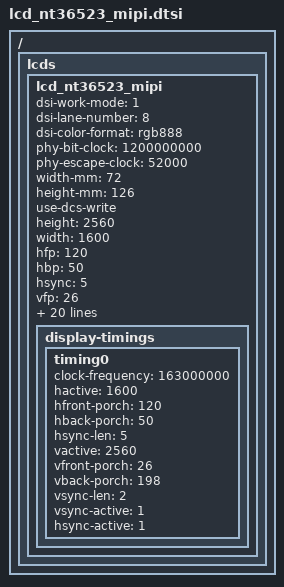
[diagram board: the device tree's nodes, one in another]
// SPDX-License-Identifier: GPL-2.0

/ { lcds: lcds {
	lcd_nt36523_mipi: lcd_nt36523_mipi {
		dsi-work-mode = <1>; /* video burst mode*/
		dsi-lane-number = <8>;
		dsi-color-format = "rgb888";

		phy-bit-clock = <1200000000>;	/* kbps */
		phy-escape-clock = <52000>;/* kHz */

		width-mm = <72>;
		height-mm = <126>;

		use-dcs-write;

		/*mipi info*/
		height = <2560>;
		width = <1600>;
		hfp = <120>;
		hbp = <50>;
		hsync = <5>;
		vfp = <26>;
		vbp = <198>;
		vsync = <2>;
		fps = <60>;
		work-mode = <0>;
		rgb-mode = <3>;
		lane-number = <8>;
		phy-freq = <1050000>;
		split-enable = <1>;
		eotp-enable = <0>;
		burst-mode = <2>;
		esd-check-enable = <0>;

		te-esd-en = <0>;

		/* DSI_CMD, DSI_MODE, timeout, len, cmd  */
		initial-command = [
			39 01 00 02 FF 20
			39 01 00 02 FB 01
			39 01 00 02 05 69
			39 01 00 02 07 32
			39 01 00 02 08 32
			39 01 00 02 0D 63
			39 01 00 02 0E 41
			39 01 00 02 0F 41
			39 01 00 02 94 00
			39 01 00 02 95 C3
			39 01 00 02 96 EB
			39 01 00 02 30 11
			39 01 00 02 58 40
			39 01 00 02 6D AA
			39 01 00 02 75 C4
			39 01 00 02 77 B3
			39 01 00 02 FF 22
			39 01 00 02 FB 01
			39 01 00 02 9F 5E
			39 01 00 02 6F 01
			39 01 00 02 70 11
			39 01 00 02 73 01
			39 01 00 02 74 87
			39 01 00 02 76 01
			39 01 00 02 77 87
			39 01 00 02 A0 3F
			39 01 00 02 A9 50
			39 01 00 02 AA 28
			39 01 00 02 AB 28
			39 01 00 02 AD 10
			39 01 00 02 B8 00
			39 01 00 02 B9 87
			39 01 00 02 BA 87
			39 01 00 02 BB 87
			39 01 00 02 BE 04
			39 01 00 02 BF 87
			39 01 00 02 C0 04
			39 01 00 02 C1 97
			39 01 00 02 C2 00
			39 01 00 02 C5 00
			39 01 00 02 C6 01
			39 01 00 02 C7 48
			39 01 00 02 CA 43
			39 01 00 02 CB 3C
			39 01 00 02 CE 00
			39 01 00 02 CF 43
			39 01 00 02 D0 3C
			39 01 00 02 D3 43
			39 01 00 02 D4 3C
			39 01 00 02 D7 00
			39 01 00 02 DC 43
			39 01 00 02 DD 3C
			39 01 00 02 E1 43
			39 01 00 02 E2 3C
			39 01 00 02 F2 00
			39 01 00 02 F3 01
			39 01 00 02 F4 48
			39 01 00 02 FF 24
			39 01 00 02 FB 01
			39 01 00 02 00 03
			39 01 00 02 01 27
			39 01 00 02 02 27
			39 01 00 02 03 27
			39 01 00 02 04 00
			39 01 00 02 05 00
			39 01 00 02 06 00
			39 01 00 02 07 04
			39 01 00 02 08 05
			39 01 00 02 09 23
			39 01 00 02 0A 22
			39 01 00 02 0B 28
			39 01 00 02 0C 28
			39 01 00 02 0D 21
			39 01 00 02 0E 29
			39 01 00 02 0F 29
			39 01 00 02 10 0C
			39 01 00 02 11 0D
			39 01 00 02 12 0E
			39 01 00 02 13 0F
			39 01 00 02 14 26
			39 01 00 02 15 26
			39 01 00 02 16 03
			39 01 00 02 17 27
			39 01 00 02 18 27
			39 01 00 02 19 27
			39 01 00 02 1A 00
			39 01 00 02 1B 00
			39 01 00 02 1C 00
			39 01 00 02 1D 04
			39 01 00 02 1E 05
			39 01 00 02 1F 23
			39 01 00 02 20 22
			39 01 00 02 21 28
			39 01 00 02 22 28
			39 01 00 02 23 21
			39 01 00 02 24 29
			39 01 00 02 25 29
			39 01 00 02 26 0C
			39 01 00 02 27 0D
			39 01 00 02 28 0E
			39 01 00 02 29 0F
			39 01 00 02 2A 26
			39 01 00 02 2B 26
			39 01 00 02 2F 02
			39 01 00 02 30 01
			39 01 00 02 33 01
			39 01 00 02 34 02
			39 01 00 02 37 22
			39 01 00 02 39 00
			39 01 00 02 3A 01
			39 01 00 02 3B 86
			39 01 00 02 3D 02
			39 01 00 02 4D 43
			39 01 00 02 4E 21
			39 01 00 02 51 12
			39 01 00 02 52 34
			39 01 00 03 55 0B 0B
			39 01 00 02 56 04
			39 01 00 02 58 10
			39 01 00 02 59 20
			39 01 00 02 5A 6A
			39 01 00 02 5B 63
			39 01 00 03 5E 00 0B
			39 01 00 02 5F 00
			39 01 00 02 65 82
			39 01 00 02 96 73
			39 01 00 02 B1 0E
			39 01 00 02 B2 0D
			39 01 00 02 C4 2F
			39 01 00 0D B6 05 00 05 00 00 00 00 00 05 05 00 00
			39 01 00 02 60 C8
			39 01 00 02 61 00
			39 01 00 02 63 A0
			39 01 00 02 91 40
			39 01 00 02 92 87
			39 01 00 02 93 1A
			39 01 00 02 94 C8
			39 01 00 02 95 80
			39 01 00 02 AB 22
			39 01 00 02 D7 55
			39 01 00 02 DA 0A
			39 01 00 02 DE 08
			39 01 00 02 DB 71
			39 01 00 02 DC 87
			39 01 00 02 DD 22
			39 01 00 02 DF 01
			39 01 00 02 E0 87
			39 01 00 02 E1 01
			39 01 00 02 E2 87
			39 01 00 02 E3 01
			39 01 00 02 E4 87
			39 01 00 02 E5 01
			39 01 00 02 E6 87
			39 01 00 02 5C 00
			39 01 00 02 5D 00
			39 01 00 02 8D 00
			39 01 00 02 8E 00
			39 01 00 02 B5 90
			39 01 00 02 C2 DF
			39 01 00 02 65 C2
			39 01 00 02 B1 0E
			39 01 00 02 B2 0D
			39 01 00 02 FF 25
			39 01 00 02 FB 01
			39 01 00 02 05 00
			39 01 00 02 19 07
			39 01 00 02 1F 6A
			39 01 00 02 20 63
			39 01 00 02 26 6A
			39 01 00 02 27 63
			39 01 00 02 33 6A
			39 01 00 02 34 63
			39 01 00 02 3F 00
			39 01 00 02 44 01
			39 01 00 02 45 48
			39 01 00 02 48 6A
			39 01 00 02 49 63
			39 01 00 02 5B 00
			39 01 00 02 5C 00
			39 01 00 02 5D 00
			39 01 00 02 5E D0
			39 01 00 02 61 6A
			39 01 00 02 62 63
			39 01 00 02 F1 10
			39 01 00 02 FF 2A
			39 01 00 02 FB 01
			39 01 00 02 64 96
			39 01 00 02 6A 9E
			39 01 00 02 76 9E
			39 01 00 02 79 96
			39 01 00 02 7C 96
			39 01 00 02 7F 96
			39 01 00 02 82 16
			39 01 00 02 85 9E
			39 01 00 02 88 96
			39 01 00 02 A2 FF
			39 01 00 02 A3 FF
			39 01 00 02 A4 F3
			39 01 00 02 A5 FF
			39 01 00 02 D6 08
			39 01 00 02 FF 26
			39 01 00 02 FB 01
			39 01 00 02 00 81
			39 01 00 02 01 30
			39 01 00 02 02 31
			39 01 00 02 0A F2
			39 01 00 02 04 5E
			39 01 00 02 06 32
			39 01 00 02 0A F5
			39 01 00 02 0C 16
			39 01 00 02 0D 0D
			39 01 00 02 0F 00
			39 01 00 02 11 00
			39 01 00 02 12 50
			39 01 00 02 13 60
			39 01 00 02 14 70
			39 01 00 02 15 00
			39 01 00 02 16 10
			39 01 00 02 17 A0
			39 01 00 02 18 86
			39 01 00 02 19 16
			39 01 00 02 1A 7F
			39 01 00 02 1B 15
			39 01 00 02 1C 90
			39 01 00 02 22 00
			39 01 00 02 23 00
			39 01 00 02 2A 16
			39 01 00 02 2B 7F
			39 01 00 02 1D 00
			39 01 00 02 1E 87
			39 01 00 02 1F 87
			39 01 00 02 24 00
			39 01 00 02 25 87
			39 01 00 02 2F 04
			39 01 00 02 30 87
			39 01 00 02 31 04
			39 01 00 02 32 9F
			39 01 00 02 39 00
			39 01 00 02 3A 87
			39 01 00 02 20 01
			39 01 00 02 33 66
			39 01 00 02 34 66
			39 01 00 02 35 66
			39 01 00 02 8B 50
			39 01 00 02 FF 25
			39 01 00 02 FB 01
			39 01 00 02 13 02
			39 01 00 02 14 41
			39 01 00 02 BC 02
			39 01 00 02 BD 41
			39 01 00 02 FF 2A
			39 01 00 02 FB 01
			39 01 00 02 99 95
			39 01 00 02 9A 03
			39 01 00 02 FF 27
			39 01 00 02 FB 01
			39 01 00 02 56 06
			39 01 00 02 58 80
			39 01 00 02 59 93
			39 01 00 02 5A 00
			39 01 00 02 5B 02
			39 01 00 02 5C 00
			39 01 00 02 5D 00
			39 01 00 02 5E 20
			39 01 00 02 5F 10
			39 01 00 02 60 00
			39 01 00 02 61 2A
			39 01 00 02 62 00
			39 01 00 02 63 01
			39 01 00 02 64 56
			39 01 00 02 65 29
			39 01 00 02 66 00
			39 01 00 02 67 01
			39 01 00 02 68 57
			39 01 00 02 3F 40
			39 01 00 02 76 02
			39 01 00 02 FF 2A
			39 01 00 02 FB 01
			39 01 00 02 22 2F
			39 01 00 02 23 08
			39 01 00 02 24 00
			39 01 00 02 25 87
			39 01 00 02 27 00
			39 01 00 02 28 1A
			39 01 00 02 29 00
			39 01 00 02 2A 1A
			39 01 00 02 2B 00
			39 01 00 02 2D 1A
			39 01 00 02 2F 00
			39 01 00 02 30 87
			39 01 00 02 32 00
			39 01 00 02 33 1A
			39 01 00 02 34 00
			39 01 00 02 35 1A
			39 01 00 02 36 00
			39 01 00 02 37 1A
			39 01 00 02 38 03
			39 01 00 02 39 87
			39 01 00 02 3B 00
			39 01 00 02 3D 1A
			39 01 00 02 3F 00
			39 01 00 02 40 1A
			39 01 00 02 41 00
			39 01 00 02 42 1A
			39 01 00 02 FF 27
			39 01 00 02 FB 01
			39 01 00 02 30 02
			39 01 00 02 76 02
			39 01 00 02 96 02
			39 01 00 02 F8 02
			39 01 00 02 FF E0
			39 01 00 02 FB 01
			39 01 00 02 14 60
			39 01 00 02 16 C0
			39 01 00 02 4F 02
			39 01 00 02 FF F0
			39 01 00 02 FB 01
			39 01 00 02 3A 08
			39 01 00 02 FF D0
			39 01 00 02 FB 01
			39 01 00 02 02 AF
			39 01 00 02 09 EE
			39 01 00 02 1C 88
			39 01 00 02 1D 08
			39 01 00 02 FF 10
			39 01 00 02 FB 01
			39 01 00 02 B9 05
			39 01 00 02 FF 20
			39 01 00 02 FB 01
			39 01 00 02 18 40
			39 01 00 02 FF 10
			39 01 00 02 FB 01
			39 01 00 02 B9 02
			39 01 00 02 35 00
			39 01 00 02 BB 13
			39 01 00 06 3B 03 C8 1A 04 04
			39 01 78 01 11
			39 01 14 01 29
		];
		sleep-in-command = [
			39 01 14 01 28
			39 01 78 01 10
		];
		sleep-out-command = [
			05 01 78 01 11
			05 01 14 01 29
		];
		read-id-command = [
			37 01 00 01 01
			14 01 00 01 04
		];

		display-timings {
			timing0 {
				clock-frequency = <163000000>;
				hactive = <1600>;
				hfront-porch = <120>;
				hback-porch = <50>;
				hsync-len = <5>;
				vactive = <2560>;
				vfront-porch = <26>;
				vback-porch = <198>;
				vsync-len = <2>;
				vsync-active = <1>;
				hsync-active = <1>;
			};
		};
	};
};};
